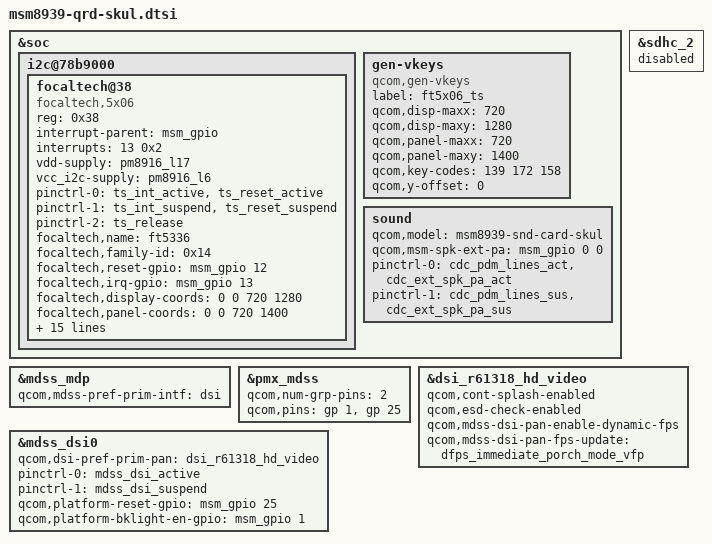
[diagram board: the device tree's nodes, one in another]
/* Copyright (c) 2014-2015, The Linux Foundation. All rights reserved.
 *
 * This program is free software; you can redistribute it and/or modify
 * it under the terms of the GNU General Public License version 2 and
 * only version 2 as published by the Free Software Foundation.
 *
 * This program is distributed in the hope that it will be useful,
 * but WITHOUT ANY WARRANTY; without even the implied warranty of
 * MERCHANTABILITY or FITNESS FOR A PARTICULAR PURPOSE.  See the
 * GNU General Public License for more details.
 */

#include "msm8939-qrd-skuk.dtsi"
#include "dsi-panel-r61318-hd-video.dtsi"

&soc {
	i2c@78b9000 { /* BLSP1 QUP5 */
		focaltech@38 {
			compatible = "focaltech,5x06";
			reg = <0x38>;
			interrupt-parent = <&msm_gpio>;
			interrupts = <13 0x2>;
			vdd-supply = <&pm8916_l17>;
			vcc_i2c-supply = <&pm8916_l6>;
			/* pins used by touchscreen */
			pinctrl-names = "pmx_ts_active","pmx_ts_suspend","pmx_ts_release";
			pinctrl-0 = <&ts_int_active &ts_reset_active>;
			pinctrl-1 = <&ts_int_suspend &ts_reset_suspend>;
			pinctrl-2 = <&ts_release>;
			focaltech,name = "ft5336";
			focaltech,family-id = <0x14>;
			focaltech,reset-gpio = <&msm_gpio 12 0x0>;
			focaltech,irq-gpio = <&msm_gpio 13 0x0>;
			focaltech,display-coords = <0 0 720 1280>;
			focaltech,panel-coords = <0 0 720 1400>;
			focaltech,button-map= <139 102 158>;
			focaltech,no-force-update;
			focaltech,i2c-pull-up;
			focaltech,group-id = <1>;
			focaltech,hard-reset-delay-ms = <20>;
			focaltech,soft-reset-delay-ms = <200>;
			focaltech,num-max-touches = <5>;
			focaltech,fw-delay-aa-ms = <30>;
			focaltech,fw-delay-55-ms = <30>;
			focaltech,fw-upgrade-id1 = <0x11>;
			focaltech,fw-upgrade-id2 = <0x11>;
			focaltech,fw-delay-readid-ms = <10>;
			focaltech,fw-delay-era-flsh-ms = <2000>;
			focaltech,fw-auto-cal;
			focaltech,ignore-id-check;
		};
	};

	gen-vkeys {
		compatible = "qcom,gen-vkeys";
		label = "ft5x06_ts";
		qcom,disp-maxx = <720>;
		qcom,disp-maxy = <1280>;
		qcom,panel-maxx = <720>;
		qcom,panel-maxy = <1400>;
		qcom,key-codes = <139 172 158>;
		qcom,y-offset = <0>;
	};

	sound {
		qcom,model = "msm8939-snd-card-skul";
		qcom,msm-spk-ext-pa = <&msm_gpio 0 0>;
		pinctrl-names = "cdc_lines_act",
				"cdc_lines_sus";
		pinctrl-0 = <&cdc_pdm_lines_act &cdc_ext_spk_pa_act>;
		pinctrl-1 = <&cdc_pdm_lines_sus &cdc_ext_spk_pa_sus>;
	};
};

&sdhc_2 {
	status = "disabled";
};

&mdss_mdp {
	qcom,mdss-pref-prim-intf = "dsi";
};

&pmx_mdss {
	qcom,num-grp-pins = <2>;
	qcom,pins = <&gp 1>, <&gp 25>;
};

&mdss_dsi0 {
	qcom,dsi-pref-prim-pan = <&dsi_r61318_hd_video>;
	pinctrl-names = "mdss_default", "mdss_sleep";
	pinctrl-0 = <&mdss_dsi_active>;
	pinctrl-1 = <&mdss_dsi_suspend>;
	qcom,platform-reset-gpio = <&msm_gpio 25 0>;
	qcom,platform-bklight-en-gpio = <&msm_gpio 1 0>;
};

&dsi_r61318_hd_video {
	qcom,cont-splash-enabled;
	qcom,esd-check-enabled;
	qcom,mdss-dsi-pan-enable-dynamic-fps;
	qcom,mdss-dsi-pan-fps-update = "dfps_immediate_porch_mode_vfp";
};
